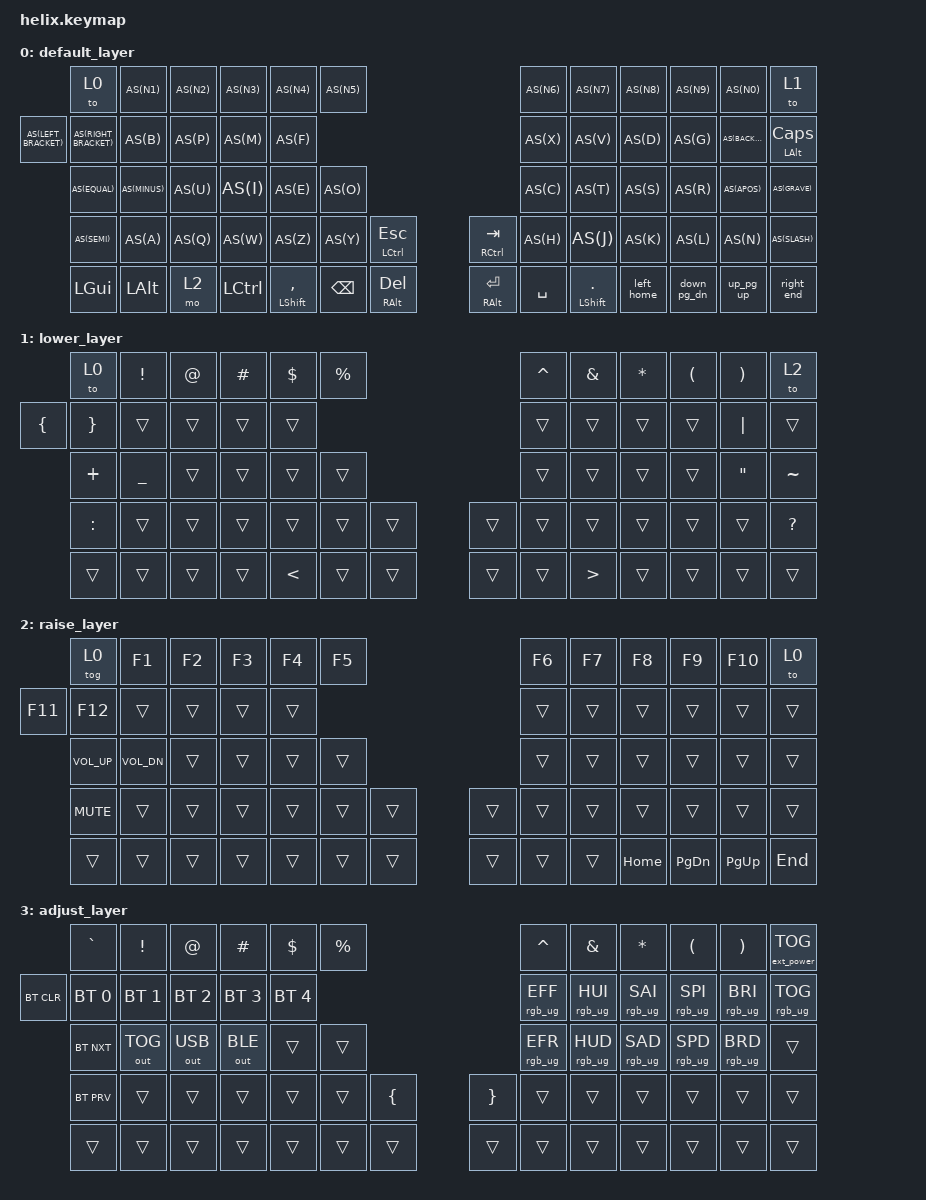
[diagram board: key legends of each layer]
/*
 * Copyright (c) 2020 The ZMK Contributors
 *
 * SPDX-License-Identifier: MIT
 */

#include <behaviors.dtsi>fine DEFAULT 0

#include <dt-bindings/zmk/keys.h>
#include <dt-bindings/zmk/ext_power.h>
#include <dt-bindings/zmk/bt.h>
#include <dt-bindings/zmk/rgb.h>
#include <dt-bindings/zmk/outputs.h>

#define LOWER  1
#define RAISE  2
#define ADJUST 3

#define AS(keycode) &as LS(keycode) keycode

/ {
        //Auto-Shift : use with AS(key)
        behaviors {
            as: auto_shift {
                compatible = "zmk,behavior-hold-tap";
                label = "AUTO_SHIFT";
                #binding-cells = <2>;
                tapping_term_ms = <135>;
                quick_tap_ms = <0>;
                flavor = "tap-preferred";
                bindings = <&kp>, <&kp>;
            };
        };

    behaviors {
        left_home: left_home {
            compatible = "zmk,behavior-mod-morph";
            label = "LEFT_HOME";
            #binding-cells = <0>;
            bindings = <&kp LEFT>, <&kp HOME>;
            mods = <(MOD_LSFT|MOD_RALT|MOD_RSFT)>;
        };
    };
        behaviors {
        up_pg_up: up_pg_up {
            compatible = "zmk,behavior-mod-morph";
            label = "UP_PGUP";
            #binding-cells = <0>;
            bindings = <&kp UP>, <&kp PG_UP>;
            mods = <(MOD_LSFT|MOD_RALT|MOD_RSFT)>;
        };
    };
    behaviors {
        down_pg_dn: down_pg_dn{
            compatible = "zmk,behavior-mod-morph";
            label = "DOWN_PG_DN";
            #binding-cells = <0>;
            bindings = <&kp DOWN>, <&kp PG_DN>;
            mods = <(MOD_LSFT|MOD_RALT|MOD_RSFT)>;
        };
    };
    behaviors {
        right_end: right_end {
            compatible = "zmk,behavior-mod-morph";
            label = "RIGHT_END";
            #binding-cells = <0>;
            bindings = <&kp RIGHT>, <&kp END>;
            mods = <(MOD_LSFT|MOD_RALT|MOD_RSFT)>;
        };
    };



    keymap {
        compatible = "zmk,keymap";

        default_layer {
            // ---------------------------------------------------------------------------------------------------------------------------------
            // | GRAVE  |   1    |   2    |   3    |   4    |   5    |                                      |   6    |   7    |   8    |   9    |   0    |  DEL   |
            // |  TAB   |   Q    |   W    |   E    |   R    |   T    |                                      |   Y    |   U    |   I    |   O    |   P    |  BSPC  |
            // |  CTRL  |   A    |   S    |   D    |   F    |   G    |                                      |   H    |   J    |   K    |   L    |   ;    |   '    |
            // |  SHIFT |   Z    |   X    |   C    |   V    |   B    |  LBKT  |                    |  RBKT  |   N    |   M    |   ,    |   .    |   /    |  RET   |
            // | ADJUST |  ESC   |  ALT   |  LGUI  | EISUU  | LOWER  | SPACE  |                    |  SPACE | RAISE  |  KANA  |  LEFT  |  DOWN  |  UP    |  RIGHT |

            bindings = <
            &to 0             AS(N1)   AS(N2)     AS(N3)            AS(N4)         AS(N5)                                           AS(N6)      AS(N7)      AS(N8)      AS(N9)      AS(N0)          &to 1
 AS(LEFT_BRACKET)  AS(RIGHT_BRACKET)   AS(B)      AS(P)             AS(M)          AS(F)                                            AS(X)       AS(V)       AS(D)       AS(G)       AS(BACKSLASH)   &mt LALT CAPS
        AS(EQUAL)          AS(MINUS)   AS(U)      AS(I)             AS(E)          AS(O)                                            AS(C)       AS(T)       AS(S)       AS(R)       AS(APOS)        AS(GRAVE)
         AS(SEMI)              AS(A)   AS(Q)      AS(W)             AS(Z)          AS(Y)  &mt LEFT_CONTROL ESC   &mt RCTRL TAB      AS(H)       AS(J)       AS(K)       AS(L)       AS(N)           AS(SLASH)
         &kp LGUI           &kp LALT   &mo 2  &kp LCTRL  &mt LSHIFT COMMA  &kp BACKSPACE          &mt RALT DEL  &mt RALT ENTER  &kp SPACE  &mt LSHFT PERIOD &left_home  &down_pg_dn &up_pg_up       &right_end
            >;
        };

        lower_layer {
            // ---------------------------------------------------------------------------------------------------------------------------------
            // |      |      |      |      |      |      |                                  |      |      |      |      |      |      |
            // |  ~   |  !   |  @   |  #   |  $   |  %   |                                  |  ^   |  &   |  *   |  (   |  )   |      |
            // |      |      |      |      |      |      |                                  |      |  _   |  +   |  {   |  }   | PIPE |
            // |      |      |      |      |      |      |  (   |                    |  )   |      |      |      | HOME | END  |      |
            // |      |      |      |      |      |      |      |                    |      |      |      |      |      |      |      |

            bindings = <
          &to 0         &kp EXCL  &kp AT  &kp HASH  &kp DOLLAR  &kp PERCENT                  &kp CARET  &kp AMPS  &kp ASTRK  &kp LEFT_PARENTHESIS  &kp RIGHT_PARENTHESIS         &to 2
 &kp LEFT_BRACE  &kp RIGHT_BRACE  &trans    &trans      &trans       &trans                     &trans    &trans     &trans                &trans               &kp PIPE        &trans
       &kp PLUS        &kp UNDER  &trans    &trans      &trans       &trans                     &trans    &trans     &trans                &trans      &kp DOUBLE_QUOTES     &kp TILDE
      &kp COLON           &trans  &trans    &trans      &trans       &trans  &trans  &trans     &trans    &trans     &trans                &trans                 &trans  &kp QUESTION
         &trans           &trans  &trans    &trans      &kp LT       &trans  &trans  &trans     &trans    &kp GT     &trans                &trans                 &trans        &trans
            >;
        };

        raise_layer {
            // ---------------------------------------------------------------------------------------------------------------------------------
            // |       |       |       |       |       |       |                                    |       |       |       |       |       |       |
            // |   `   |   1   |   2   |   3   |   4   |   5   |                                    |   6   |   7   |   8   |   9   |   0   |  DEL  |
            // |       |  F1   |  F2   |  F3   |  F4   |  F5   |                                    |  F6   |   -   |   =   |   [   |   ]   |   \   |
            // |       |  F7   |  F8   |  F9   |  F10  |  F11  |       |                    |       |  F12  |       | PSCRN | PG_DN | PG_UP |       |
            // |       |       |       |       |       |       |       |                    |       |       |       | NEXT  | VOL-  | VOL+  | PLAY  |

            bindings = <
       &tog 0        &kp F1  &kp F2  &kp F3  &kp F4  &kp F5                  &kp F6  &kp F7    &kp F8     &kp F9    &kp F10    &to 0
      &kp F11       &kp F12  &trans  &trans  &trans  &trans                  &trans  &trans    &trans     &trans     &trans   &trans
 &kp C_VOL_UP  &kp K_VOL_DN  &trans  &trans  &trans  &trans                  &trans  &trans    &trans     &trans     &trans   &trans
   &kp C_MUTE        &trans  &trans  &trans  &trans  &trans  &trans  &trans  &trans  &trans    &trans     &trans     &trans   &trans
       &trans        &trans  &trans  &trans  &trans  &trans  &trans  &trans  &trans  &trans  &kp HOME  &kp PG_DN  &kp PG_UP  &kp END
            >;
        };

        adjust_layer {
            // ---------------------------------------------------------------------------------------------------------------------------------
            // |    `     |    !     |    @     |    #     |    $     |    %     |                                          |    ^     |    &     |    *     |    (     |    )     |  EP TOG  |
            // |  BT CLR  | BT SEL0  | BT SEL1  | BT SEL2  | BGT SEL3 | BT SEL4  |                                          | RGB EFF+ | RGB HUE+ | RGB SAT+ | RGB SPD+ | RGB BRI+ | RGB TOG  |
            // |  BT NXT  | OUT TOG  | OUT USB  | OUT BLE  |          |          |                                          | RGB EFF- | RGB HUE- | RGB SAT- | RGB SPD- | RGB BRI- |          |
            // |  BT PRV  |          |          |          |          |          |    {     |                    |    }     |          |          |          |          |          |          |
            // |          |          |          |          |          |          |          |                    |          |          |          |          |          |          |          |

            bindings = <
  &kp GRAVE      &kp EXCL        &kp AT      &kp HASH      &kp DLLR     &kp PRCNT                            &kp CARET         &kp AMPS        &kp ASTRK         &kp LPAR         &kp RPAR  &ext_power EP_TOG
 &bt BT_CLR  &bt BT_SEL 0  &bt BT_SEL 1  &bt BT_SEL 2  &bt BT_SEL 3  &bt BT_SEL 4                      &rgb_ug RGB_EFF  &rgb_ug RGB_HUI  &rgb_ug RGB_SAI  &rgb_ug RGB_SPI  &rgb_ug RGB_BRI    &rgb_ug RGB_TOG
 &bt BT_NXT  &out OUT_TOG  &out OUT_USB  &out OUT_BLE        &trans        &trans                      &rgb_ug RGB_EFR  &rgb_ug RGB_HUD  &rgb_ug RGB_SAD  &rgb_ug RGB_SPD  &rgb_ug RGB_BRD             &trans
 &bt BT_PRV        &trans        &trans        &trans        &trans        &trans  &kp LBRC  &kp RBRC           &trans           &trans           &trans           &trans           &trans             &trans
     &trans        &trans        &trans        &trans        &trans        &trans    &trans    &trans           &trans           &trans           &trans           &trans           &trans             &trans
            >;
        };
    };
};
